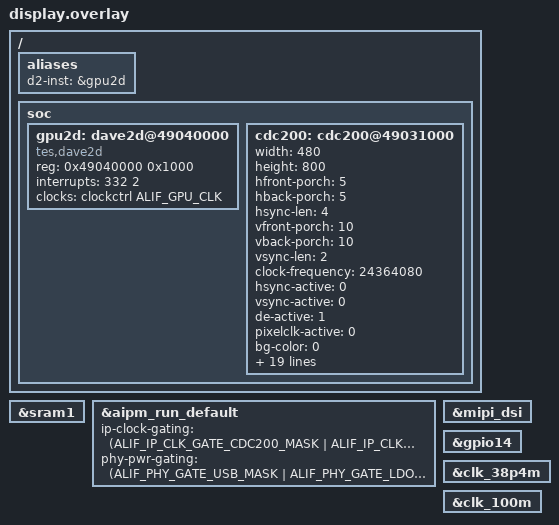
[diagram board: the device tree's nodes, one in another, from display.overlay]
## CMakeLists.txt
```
# Copyright (c) 2026 Alif Semiconductor
# SPDX-License-Identifier: Apache-2.0

cmake_minimum_required(VERSION 3.20.0)
find_package(Zephyr REQUIRED HINTS $ENV{ZEPHYR_BASE})
project(usb_host_uvc)

target_sources(app PRIVATE src/main.c)
target_sources_ifdef(CONFIG_DISPLAY app PRIVATE src/display.c)

# Place USB host DMA buffers in SRAM0
zephyr_linker_sources(DATA_SECTIONS ${CMAKE_CURRENT_SOURCE_DIR}/uhc_dma.ld)
```

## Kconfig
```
# Copyright (c) 2026 Alif Semiconductor
# SPDX-License-Identifier: Apache-2.0

mainmenu "USB Host UVC Capture Sample"

config SAMPLE_UVC_FORMAT_INDEX
	int "Format to stream (bFormatIndex)"
	range 0 255
	default 0
	help
	  bFormatIndex of the video format to request from the device. 0
	  selects the first format the device lists or, with the display, any
	  format the display can show.

config SAMPLE_UVC_FRAME_INDEX
	int "Frame size to stream (bFrameIndex)"
	range 0 255
	default 0
	help
	  bFrameIndex of the frame size to request within the selected format.
	  0 selects the format's default frame (bDefaultFrameIndex) or, with
	  the display, the largest frame the display shows without shrinking
	  it, turned by 90 degrees if need be.

config SAMPLE_UVC_DISPLAY_ROTATE_CCW
	bool "Turn frames counter-clockwise on the display"
	depends on DISPLAY
	help
	  Frames that fill more of the display turned by 90 degrees, such as
	  landscape frames on the DK's portrait panel, are turned clockwise,
	  which puts the top of the picture on the right of the panel. Select
	  this to turn them counter-clockwise instead.

config SAMPLE_UVC_FRAME_BUFFER_SIZE
	int "Frame reassembly buffer size in bytes"
	default 614400
	help
	  Size of the buffer each frame is reassembled into, in SRAM0. The
	  device's dwMaxVideoFrameSize for the negotiated format must fit. The
	  default holds a 640x480 frame at 16 bits per pixel.

config SAMPLE_UVC_TRACE_XFERS
	int "Log the first N transfers"
	range 0 64
	default 0
	help
	  Record the length and first bytes of the first N bulk or isochronous
	  IN transfers after the first stream starts and log them once N have
	  arrived, to debug payload framing. 0 disables the trace.

source "Kconfig.zephyr"
```

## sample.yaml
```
sample:
  name: USB Host UVC Capture
  description: |
    USB host mode sample that enumerates a USB Video Class device streaming
    over a bulk endpoint, negotiates a format with Probe/Commit, reassembles
    frames from the UVC payloads, validates them and logs frame rate and
    throughput. Tested on the E8 DK with an E1C SK running the video_uvc
    sample as the camera. Optionally shows the video on the DK display.
tests:
  sample.drivers.usb.host_uvc:
    extra_args:
      - DTC_OVERLAY_FILE=boards/alif_usb_host.overlay
    integration_platforms:
      - alif_e8_dk/ae822fa0e5597xx0/rtss_hp
    platform_allow:
      - alif_e8_dk/ae822fa0e5597xx0/rtss_hp
      - alif_e8_dk/ae822fa0e5597xx0/rtss_he
      - alif_e7_dk/ae722f80f55d5xx/rtss_hp
      - alif_e7_dk/ae722f80f55d5xx/rtss_he
    tags:
      - usb
      - host
      - video
    harness: keyboard
  sample.drivers.usb.host_uvc.display:
    extra_args:
      - DTC_OVERLAY_FILE=boards/alif_usb_host.overlay
      - EXTRA_DTC_OVERLAY_FILE=display.overlay
      - EXTRA_CONF_FILE=display.conf
    integration_platforms:
      - alif_e8_dk/ae822fa0e5597xx0/rtss_hp
    platform_allow:
      - alif_e8_dk/ae822fa0e5597xx0/rtss_hp
      - alif_e8_dk/ae822fa0e5597xx0/rtss_he
      - alif_e7_dk/ae722f80f55d5xx/rtss_hp
      - alif_e7_dk/ae722f80f55d5xx/rtss_he
    tags:
      - usb
      - host
      - video
      - display
    harness: keyboard
```

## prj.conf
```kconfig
# Copyright (c) 2026 Alif Semiconductor
# SPDX-License-Identifier: Apache-2.0

CONFIG_LOG=y
CONFIG_LOG_DEFAULT_LEVEL=3
CONFIG_LOG_BUFFER_SIZE=16384

CONFIG_USB_HOST_STACK=y
CONFIG_UHC_DWC3=y
CONFIG_UVC_HOST=y

CONFIG_MAIN_STACK_SIZE=4096
CONFIG_SYSTEM_WORKQUEUE_STACK_SIZE=2048
```

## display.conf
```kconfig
# Copyright (c) 2026 Alif Semiconductor
# SPDX-License-Identifier: Apache-2.0

# Show the captured video on the DK display (use with display.overlay)
CONFIG_DISPLAY=y
CONFIG_MIPI_DSI=y
CONFIG_GPIO=y

# Room for a frame as large as the 480x800 panel at 16 bits per pixel
CONFIG_SAMPLE_UVC_FRAME_BUFFER_SIZE=768000

# Turn frames with the D/AVE2D GPU through AIPL, converting YUY2 with
# Helium. Set CONFIG_AIPL=n to draw everything with the CPU.
CONFIG_AIPL=y
CONFIG_DAVE2D=y
CONFIG_AIPL_CUSTOM_VIDEO_ALLOC=n
CONFIG_AIPL_COLOR_CORRECTION=n
CONFIG_AIPL_DEMOSAICING=n
CONFIG_AIPL_CONVERT_YUY2_TO_RGB565=y
```

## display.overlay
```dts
/*
 * Copyright (c) 2026 Alif Semiconductor
 * SPDX-License-Identifier: Apache-2.0
 *
 * Show the captured video on the Ensemble DK display: the MW405 480x800
 * MIPI DSI panel driven by the CDC200 controller, one RGB565 layer. The
 * D/AVE2D GPU turns frames for the portrait panel.
 * Use together with display.conf (see README.rst).
 */

#include <dt-bindings/misc/alif_aipm_common.h>

/ {
	aliases {
		d2-inst = &gpu2d;
	};

	soc {
		gpu2d: dave2d@49040000 {
			compatible = "tes,dave2d";
			reg = <0x49040000 0x1000>;
			interrupts = <332 2>;
			clocks = <&clockctrl ALIF_GPU_CLK>;
		};

		cdc200: cdc200@49031000 {
			width = <480>;
			height = <800>;
			hfront-porch = <5>;
			hback-porch = <5>;
			hsync-len = <4>;
			vfront-porch = <10>;
			vback-porch = <10>;
			vsync-len = <2>;
			clock-frequency = <24364080>;
			hsync-active = <0>;
			vsync-active = <0>;
			de-active = <1>;
			pixelclk-active = <0>;
			bg-color = <0>;
			enable-l1 = <1>;
			pixel-fmt-l1 = "rgb-565";
			def-back-color-l1 = <0>;
			win-x0-l1 = <0>;
			win-y0-l1 = <0>;
			win-x1-l1 = <480>;
			win-y1-l1 = <800>;
			blend-factor1-l1 = <4>;
			blend-factor2-l1 = <5>;
			const-alpha-l1 = <0xff>;
			enable-l2 = <0>;
			pixel-fmt-l2 = "undefined";
			win-x0-l2 = <0>;
			win-y0-l2 = <0>;
			win-x1-l2 = <0>;
			win-y1-l2 = <0>;
			blend-factor1-l2 = <6>;
			blend-factor2-l2 = <7>;
			const-alpha-l2 = <0xff>;
		};
	};
};

/* The D/AVE2D heap and the frame it turns are kept in SRAM1 */
&sram1 {
	status = "okay";
};

/* Keep the USB PHY powered and add the display blocks */
&aipm_run_default {
	ip-clock-gating = <(ALIF_IP_CLK_GATE_CDC200_MASK |
			    ALIF_IP_CLK_GATE_MIPI_DSI_MASK |
			    ALIF_IP_CLK_GATE_GPU_MASK)>;
	phy-pwr-gating = <(ALIF_PHY_GATE_USB_MASK | ALIF_PHY_GATE_LDO_MASK |
			   ALIF_PHY_GATE_MIPI_TX_DPHY_MASK |
			   ALIF_PHY_GATE_MIPI_RX_DPHY_MASK |
			   ALIF_PHY_GATE_MIPI_PLL_DPHY_MASK)>;
};

&mipi_dsi {
	status = "okay";
};

/* Camera/display MIPI switch select on the E4/E6/E8 DK */
&gpio14 {
	status = "okay";
};

&clk_38p4m {
	status = "okay";
};

&clk_100m {
	status = "okay";
};
```

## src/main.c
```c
/*
 * Copyright (c) 2026 Alif Semiconductor
 * SPDX-License-Identifier: Apache-2.0
 *
 * USB Host UVC Capture Sample
 *
 * Brings up the DWC3 controller in host mode and captures video from a USB
 * Video Class (UVC) device that streams over a bulk endpoint, such as an
 * Alif board running the video_uvc sample, or over an isochronous one, such
 * as a webcam:
 *
 *   1. Wait for a device to be connected and enumerate it
 *   2. Parse the configuration descriptor for the VideoStreaming interface,
 *      its formats and frame sizes, and its alternate settings
 *   3. SET_CONFIGURATION and, for bulk, configure the bulk IN endpoint
 *   4. Negotiate a format and frame size with Probe/Commit
 *   5. Isochronous: select the alternate setting that carries the
 *      negotiated payload size and configure its endpoint
 *   6. Keep transfers queued, reassemble frames from the UVC payloads,
 *      validate each frame and log statistics once per second
 *   7. With display.overlay and display.conf, show each valid frame on the
 *      DK display (src/display.c) from a thread of its own
 *
 * Build:
 *   west build -b alif_e8_dk/ae822fa0e5597xx0/rtss_hp \
 *     alif/samples/drivers/usb/usb_host_uvc \
 *     -- -DDTC_OVERLAY_FILE=boards/alif_usb_host.overlay
 */

#include <string.h>

#include <zephyr/kernel.h>
#include <zephyr/device.h>
#include <zephyr/usb/usbh.h>
#include <zephyr/usb/usb_ch9.h>
#include <zephyr/drivers/usb/uhc.h>
#include <zephyr/drivers/usb/uhc_dwc3.h>
#include <zephyr/sys/byteorder.h>

#include "display.h"
#include <zephyr/drivers/usb/uvc_host.h>

#include <zephyr/logging/log.h>
LOG_MODULE_REGISTER(usb_host_uvc, LOG_LEVEL_INF);

#define UHC_NODE DT_NODELABEL(zephyr_uhc0)

#if !DT_NODE_EXISTS(UHC_NODE)
#error "zephyr_uhc0 node not found. Check overlay."
#endif

static const struct device *uhc_dev = DEVICE_DT_GET(UHC_NODE);

USBH_CONTROLLER_DEFINE(sample_uhs_ctx, DEVICE_DT_GET(UHC_NODE));

/* Bulk IN transfers kept in flight, each receiving into its own chunk */
#define NUM_CHUNKS	4
#define CHUNK_SIZE	16384

/*
 * Isochronous IN transfers kept in flight, one per service interval. On
 * High Speed the 32 cover 4 ms. Each buffer holds the most a High-Speed
 * endpoint carries per microframe (3 x 1024 bytes) and is aligned so it
 * never crosses a 64 KiB boundary.
 */
#define NUM_ISO_XFERS	32
#define ISO_BUF_SIZE	4096

/* Wait for a completion before checking that the device is still there */
#define REAP_TIMEOUT_MS	1000

/* A second frame buffer lets the display show one frame while the next is
 * received.
 */
#define NUM_FRAME_BUFS	(IS_ENABLED(CONFIG_DISPLAY) ? 2 : 1)

/*
 * The USB DMA cannot reach TCM, so the chunks live in SRAM0 (placed by
 * uhc_dma.ld). Aligning each chunk to its size keeps it inside one 64 KiB
 * window, as the controller requires. The frame buffer is only written by
 * the CPU but is too large for TCM.
 */
#define SRAM0_SECTION __attribute__((section(".sram0.bss.uhc_dma.uvc")))

static uint8_t chunks[NUM_CHUNKS][CHUNK_SIZE] __aligned(CHUNK_SIZE)
	SRAM0_SECTION;
static uint8_t iso_bufs[NUM_ISO_XFERS][ISO_BUF_SIZE] __aligned(ISO_BUF_SIZE)
	SRAM0_SECTION;
static uint8_t frame_bufs[NUM_FRAME_BUFS][CONFIG_SAMPLE_UVC_FRAME_BUFFER_SIZE]
	__aligned(64) SRAM0_SECTION;
static int frame_buf_idx;

static uint8_t cfg_desc[UHC_DWC3_CTRL_MAX_LEN];
static struct uvc_device uvc;
static struct uvc_stream stream;

/* What the negotiated format lets us check about each frame */
static struct {
	bool mjpeg;
	size_t expected_size;	/* Uncompressed frames: exact size, else 0 */
} check;

static struct {
	uint32_t frames;
	uint32_t bad_frames;
	uint64_t bytes;
	uint32_t timeouts;
	uint32_t lost;		/* Isochronous transfers that lost their data */
	/* Totals across the window, logged once per second */
	uint32_t win_frames;
	uint64_t win_bytes;
	uint32_t win_start;
} stats;

#if CONFIG_SAMPLE_UVC_TRACE_XFERS > 0
static struct {
	uint16_t len;
	uint8_t head[4];
} trace[CONFIG_SAMPLE_UVC_TRACE_XFERS];
static int trace_count;

/* Record a transfer; log them all once the trace is full */
static void trace_xfer(const uint8_t *buf, size_t len, size_t xfer_len)
{
	uint32_t offset = 0;

	if (trace_count >= ARRAY_SIZE(trace)) {
		return;
	}

	trace[trace_count].len = len;
	memcpy(trace[trace_count].head, buf, MIN(len, 4));
	if (++trace_count < ARRAY_SIZE(trace)) {
		return;
	}

	/* Offset is counted from the end of the last short transfer */
	for (int i = 0; i < trace_count; i++) {
		const uint8_t *h = trace[i].head;

		LOG_INF("xfer %3d: off %6u len %5u%s %02x %02x %02x %02x", i,
			offset, trace[i].len,
			trace[i].len < xfer_len ? " short" : "      ",
			h[0], h[1], h[2], h[3]);
		offset = (trace[i].len < xfer_len) ? 0 : offset + trace[i].len;
	}
}
#else
static inline void trace_xfer(const uint8_t *buf, size_t len, size_t xfer_len)
{
}
#endif

static bool port_connected(void)
{
	volatile uint32_t *portsc =
		(volatile uint32_t *)(DT_REG_ADDR(UHC_NODE) + 0x420);

	return (*portsc & BIT(0)) != 0;
}

static int usb_host_event_cb(const struct device *dev,
			     const struct uhc_event *const event)
{
	switch (event->type) {
	case UHC_EVT_DEV_CONNECTED_FS:
		LOG_INF(">>> USB device connected (Full Speed)");
		break;
	case UHC_EVT_DEV_CONNECTED_HS:
		LOG_INF(">>> USB device connected (High Speed)");
		break;
	case UHC_EVT_DEV_REMOVED:
		LOG_INF(">>> USB device disconnected");
		break;
	default:
		break;
	}

	return 0;
}

#if defined(CONFIG_DISPLAY)
/*
 * Frames are drawn by a thread of their own, so that the stream keeps being
 * received meanwhile: an isochronous device does not wait for the host. A
 * frame that completes while the previous one is still being drawn is not
 * shown.
 */
static K_SEM_DEFINE(display_sem, 0, 1);
static atomic_t display_busy;
static const uint8_t *display_buf;
static size_t display_len;

static void display_thread(void *p1, void *p2, void *p3)
{
	ARG_UNUSED(p1);
	ARG_UNUSED(p2);
	ARG_UNUSED(p3);

	while (true) {
		k_sem_take(&display_sem, K_FOREVER);
		uvc_display_frame(display_buf, display_len);
		atomic_clear(&display_busy);
	}
}

K_THREAD_DEFINE(display_tid, 2048, display_thread, NULL, NULL, NULL,
		K_PRIO_PREEMPT(5), 0, 0);

static void show_frame(const uint8_t *frame, size_t len)
{
	if (!atomic_cas(&display_busy, 0, 1)) {
		return;
	}

	display_buf = frame;
	display_len = len;

	/* Receive the next frames into the other buffer meanwhile */
	frame_buf_idx = (frame_buf_idx + 1) % NUM_FRAME_BUFS;
	uvc_stream_set_buffer(&stream, frame_bufs[frame_buf_idx],
			      sizeof(frame_bufs[0]));

	k_sem_give(&display_sem);
}

/* Let the frame being drawn finish before the display format changes */
static void display_wait_idle(void)
{
	while (atomic_get(&display_busy)) {
		k_sleep(K_MSEC(1));
	}
}
#else
static void show_frame(const uint8_t *frame, size_t len)
{
}

static void display_wait_idle(void)
{
}
#endif

/* JPEG: SOI first; EOI last, allowing for a few bytes of zero padding */
static bool jpeg_ok(const uint8_t *frame, size_t len)
{
	size_t end = len;

	if (len < 4 || frame[0] != 0xFF || frame[1] != 0xD8) {
		return false;
	}

	while (end > 2 && len - end < 16 && frame[end - 1] == 0x00) {
		end--;
	}

	return frame[end - 2] == 0xFF && frame[end - 1] == 0xD9;
}

static void frame_done(const uint8_t *frame, size_t len, bool err)
{
	bool bad = err;

	if (!bad && check.mjpeg) {
		bad = !jpeg_ok(frame, len);
	} else if (!bad && check.expected_size != 0) {
		bad = (len != check.expected_size);
	}

	if (stats.frames == 0) {
		LOG_INF("First frame: %zu bytes%s, starts %02x %02x %02x %02x",
			len, bad ? " (bad)" : "", len > 0 ? frame[0] : 0,
			len > 1 ? frame[1] : 0, len > 2 ? frame[2] : 0,
			len > 3 ? frame[3] : 0);
	}

	if (bad && stats.bad_frames < 10) {
		LOG_WRN("Bad frame #%u: %zu bytes (expected %zu)%s", stats.frames,
			len, check.expected_size,
			err ? " (error flagged in stream)" : "");
	}

	if (!bad) {
		show_frame(frame, len);
	}

	stats.frames++;
	stats.bad_frames += bad ? 1 : 0;
	stats.bytes += len;
	stats.win_frames++;
	stats.win_bytes += len;
}

static void log_stats(void)
{
	uint32_t now = k_uptime_get_32();
	uint32_t ms = now - stats.win_start;

	if (ms < 1000) {
		return;
	}

	uint32_t fps_x10 = stats.win_frames * 10000U / ms;
	uint32_t kbps = (uint32_t)(stats.win_bytes / ms); /* bytes/ms = KB/s */

	LOG_INF("%u.%u fps, %u KB/s, avg %u B/frame | frames %u bad %u "
		"| hdr err %u, stream err %u, overflow %u, timeouts %u, lost %u",
		fps_x10 / 10, fps_x10 % 10, kbps,
		stats.win_frames ? (uint32_t)(stats.win_bytes / stats.win_frames) : 0,
		stats.frames, stats.bad_frames, stream.bad_headers,
		stream.err_payloads, stream.overflows, stats.timeouts,
		stats.lost);

	stats.win_frames = 0;
	stats.win_bytes = 0;
	stats.win_start = now;
}

static void list_formats(void)
{
	char name[5];

	LOG_INF("UVC %x.%02x, VideoStreaming interface %u, %s EP 0x%02x mps %u",
		uvc.bcd_uvc >> 8, uvc.bcd_uvc & 0xFF, uvc.vs_iface,
		uvc.ep_type == USB_EP_TYPE_BULK ? "bulk" : "isochronous",
		uvc.ep, uvc.ep_mps);

	for (int i = 0; i < uvc.num_alts; i++) {
		LOG_INF("  Alt %u: %u bytes per interval, bInterval %u",
			uvc.alts[i].alt, uvc_alt_payload(&uvc.alts[i]),
			uvc.alts[i].interval);
	}

	for (int i = 0; i < uvc.num_formats; i++) {
		const struct uvc_format *fmt = &uvc.formats[i];

		LOG_INF("  Format %u: %s%s", fmt->index,
			uvc_format_name(fmt, name),
			fmt->bpp ? "" : " (compressed)");

		for (int j = 0; j < uvc.num_frames; j++) {
			const struct uvc_frame *frm = &uvc.frames[j];

			if (frm->format_index != fmt->index) {
				continue;
			}
			LOG_INF("    Frame %u: %ux%u, default %u.%u fps",
				frm->index, frm->width, frm->height,
				frm->default_interval ?
					10000000U / frm->default_interval : 0,
				frm->default_interval ?
					(100000000U / frm->default_interval) % 10 : 0);
		}
	}
}

/*
 * The largest frame the display shows without shrinking it, of the format
 * selected in Kconfig or, with 0, of any format the display can show.
 */
static const struct uvc_frame *select_display_frame(
	const struct uvc_format **fmt_out)
{
	const struct uvc_frame *best = NULL;
	uint32_t best_area = 0;

	for (int i = 0; i < uvc.num_frames; i++) {
		const struct uvc_frame *frm = &uvc.frames[i];
		const struct uvc_format *fmt =
			uvc_find_format(&uvc, frm->format_index);
		uint32_t area = (uint32_t)frm->width * frm->height;

		if (fmt == NULL ||
		    (CONFIG_SAMPLE_UVC_FORMAT_INDEX != 0 &&
		     fmt->index != CONFIG_SAMPLE_UVC_FORMAT_INDEX) ||
		    !uvc_display_fits(fmt, frm->width, frm->height) ||
		    area * fmt->bpp / 8 > CONFIG_SAMPLE_UVC_FRAME_BUFFER_SIZE ||
		    area <= best_area) {
			continue;
		}

		best = frm;
		best_area = area;
		*fmt_out = fmt;
	}

	return best;
}

/*
 * Pick the format and frame selected in Kconfig (0 = default). With the
 * display and no frame selected, the frame that fills the display best.
 */
static const struct uvc_frame *select_frame(const struct uvc_format **fmt_out)
{
	const struct uvc_format *fmt;
	const struct uvc_frame *frame;
	uint8_t frame_index;

	if (CONFIG_SAMPLE_UVC_FRAME_INDEX == 0) {
		frame = select_display_frame(fmt_out);
		if (frame != NULL) {
			LOG_INF("Format %u frame %u fills the display best",
				frame->format_index, frame->index);
			return frame;
		}
	}

	if (CONFIG_SAMPLE_UVC_FORMAT_INDEX == 0) {
		fmt = &uvc.formats[0];
	} else {
		fmt = uvc_find_format(&uvc, CONFIG_SAMPLE_UVC_FORMAT_INDEX);
	}

	if (fmt == NULL) {
		LOG_ERR("Format %u not found", CONFIG_SAMPLE_UVC_FORMAT_INDEX);
		return NULL;
	}

	frame_index = CONFIG_SAMPLE_UVC_FRAME_INDEX ?
		      CONFIG_SAMPLE_UVC_FRAME_INDEX : fmt->default_frame;

	*fmt_out = fmt;

	return uvc_find_frame(&uvc, fmt->index, frame_index);
}

static int read_config_descriptor(size_t *len)
{
	uint8_t hdr[9];
	uint16_t total;
	int ret;

	ret = uhc_dwc3_control_transfer(uhc_dev, 0x80, USB_SREQ_GET_DESCRIPTOR,
					USB_DESC_CONFIGURATION << 8, 0,
					sizeof(hdr), hdr);
	if (ret < (int)sizeof(hdr)) {
		return ret < 0 ? ret : -EIO;
	}

	total = sys_get_le16(&hdr[2]);
	if (total > sizeof(cfg_desc)) {
		LOG_WRN("Config descriptor is %u bytes, reading the first %zu",
			total, sizeof(cfg_desc));
		total = sizeof(cfg_desc);
	}

	ret = uhc_dwc3_control_transfer(uhc_dev, 0x80, USB_SREQ_GET_DESCRIPTOR,
					USB_DESC_CONFIGURATION << 8, 0,
					total, cfg_desc);
	if (ret < 0) {
		return ret;
	}

	*len = ret;

	return 0;
}

/*
 * Size of each bulk IN transfer: whole packets, at most one chunk. A payload
 * that fills dwMaxPayloadTransferSize ends without a short packet, so the
 * transfers must then split it exactly, or one would run on into the header
 * of the next payload.
 */
static size_t xfer_size(uint32_t max_payload)
{
	size_t step = ROUND_UP(uvc.ep_mps, UHC_DWC3_BUF_ALIGN);
	size_t len = MIN(CHUNK_SIZE, ROUND_UP(max_payload, step));

	if (max_payload % uvc.ep_mps == 0) {
		while (len > step && max_payload % len != 0) {
			len -= step;
		}
	}

	return len;
}

/*
 * Select the isochronous alternate setting that carries the negotiated
 * payloads, configure its endpoint and select it, which starts the stream.
 * Returns the transfer size.
 */
static int start_isoch(uint32_t max_payload)
{
	const struct uvc_alt *alt = uvc_select_alt(&uvc, max_payload);
	uint32_t len;
	int ret;

	if (alt == NULL) {
		LOG_ERR("No alternate setting carries %u byte payloads",
			max_payload);
		return -ENOTSUP;
	}

	len = uvc_alt_payload(alt);
	LOG_INF("Alternate setting %u: %u bytes per interval, bInterval %u",
		alt->alt, len, alt->interval);

	if (len > ISO_BUF_SIZE) {
		return -ENOTSUP;
	}

	ret = uhc_dwc3_configure_isoch_in(uhc_dev, uvc.ep, alt->mps,
					  alt->interval);
	if (ret) {
		LOG_ERR("Configuring EP 0x%02x failed: %d", uvc.ep, ret);
		return ret;
	}

	ret = uhc_dwc3_control_transfer(uhc_dev, 0x01, USB_SREQ_SET_INTERFACE,
					alt->alt, uvc.vs_iface, 0, NULL);
	if (ret < 0) {
		LOG_ERR("SET_INTERFACE %u alt %u failed: %d", uvc.vs_iface,
			alt->alt, ret);
		return ret;
	}

	return len;
}

/* Enumerate the device and get it streaming; returns the transfer size */
static int setup_stream(void)
{
	const struct uvc_format *fmt;
	const struct uvc_frame *frame;
	struct usb_device_descriptor desc;
	struct uvc_probe probe;
	uint32_t max_payload;
	uint32_t max_frame;
	size_t cfg_len;
	char name[5];
	int xfer_len;
	int ret;

	ret = uhc_dwc3_enumerate_device(uhc_dev, &desc);
	if (ret) {
		LOG_ERR("Enumeration failed: %d", ret);
		return ret;
	}

	LOG_INF("Device: VID=0x%04x PID=0x%04x",
		sys_le16_to_cpu(desc.idVendor), sys_le16_to_cpu(desc.idProduct));

	ret = read_config_descriptor(&cfg_len);
	if (ret) {
		LOG_ERR("Reading the config descriptor failed: %d", ret);
		return ret;
	}

	ret = uvc_parse_config(cfg_desc, cfg_len, &uvc);
	if (ret == -ENODEV) {
		LOG_ERR("Not a USB Video Class device");
		return ret;
	} else if (ret) {
		LOG_ERR("No usable VideoStreaming interface found");
		return ret;
	}

	list_formats();

	if (uvc.ep_type != USB_EP_TYPE_BULK && uvc.ep_type != USB_EP_TYPE_ISO) {
		LOG_ERR("Streaming endpoint type %u is not supported",
			uvc.ep_type);
		return -ENOTSUP;
	}

	frame = select_frame(&fmt);
	if (frame == NULL) {
		LOG_ERR("Frame %u not found", CONFIG_SAMPLE_UVC_FRAME_INDEX);
		return -EINVAL;
	}

	ret = uhc_dwc3_control_transfer(uhc_dev, 0x00,
					USB_SREQ_SET_CONFIGURATION,
					uvc.cfg_val, 0, 0, NULL);
	if (ret < 0) {
		LOG_ERR("SET_CONFIGURATION failed: %d", ret);
		return ret;
	}

	if (uvc.ep_type == USB_EP_TYPE_BULK) {
		ret = uhc_dwc3_configure_bulk_in(uhc_dev, uvc.ep, uvc.ep_mps);
		if (ret) {
			LOG_ERR("Configuring EP 0x%02x failed: %d", uvc.ep,
				ret);
			return ret;
		}
	}

	ret = uvc_negotiate(uhc_dev, &uvc, frame, &probe);
	if (ret) {
		return ret;
	}

	/* Go with the format and frame the device settled on */
	if (probe.bFormatIndex != fmt->index ||
	    probe.bFrameIndex != frame->index) {
		fmt = uvc_find_format(&uvc, probe.bFormatIndex);
		frame = uvc_find_frame(&uvc, probe.bFormatIndex,
				       probe.bFrameIndex);
		if (fmt == NULL || frame == NULL) {
			LOG_ERR("Device committed an unknown format/frame");
			return -EINVAL;
		}
	}

	max_payload = sys_le32_to_cpu(probe.dwMaxPayloadTransferSize);
	max_frame = sys_le32_to_cpu(probe.dwMaxVideoFrameSize);

	LOG_INF("Streaming format %u (%s) frame %u: %ux%u, interval %u00 ns",
		fmt->index, uvc_format_name(fmt, name), frame->index,
		frame->width, frame->height,
		sys_le32_to_cpu(probe.dwFrameInterval));
	LOG_INF("  dwMaxVideoFrameSize %u, dwMaxPayloadTransferSize %u",
		max_frame, max_payload);

	if (max_payload == 0) {
		LOG_ERR("Device reported a zero payload size");
		return -EINVAL;
	}

	if (max_frame > sizeof(frame_bufs[0])) {
		LOG_ERR("Frames of up to %u bytes do not fit the %zu byte "
			"buffer, raise CONFIG_SAMPLE_UVC_FRAME_BUFFER_SIZE",
			max_frame, sizeof(frame_bufs[0]));
		return -ENOMEM;
	}

	check.mjpeg = (fmt->subtype == UVC_VS_FORMAT_MJPEG);
	check.expected_size = (fmt->subtype == UVC_VS_FORMAT_UNCOMPRESSED) ?
		(size_t)frame->width * frame->height * fmt->bpp / 8 : 0;

	display_wait_idle();
	uvc_display_set_format(fmt, frame->width, frame->height);

	uvc_stream_init(&stream, max_payload, frame_bufs[frame_buf_idx],
			sizeof(frame_bufs[0]), frame_done);
	memset(&stats, 0, sizeof(stats));
	stats.win_start = k_uptime_get_32();

	if (uvc.ep_type == USB_EP_TYPE_ISO) {
		xfer_len = start_isoch(max_payload);
	} else {
		xfer_len = xfer_size(max_payload);
	}

	return xfer_len;
}

/* Receive until the device goes away or the stream fails */
static void run_isoch(size_t xfer_len)
{
	uint8_t *buf;
	int ret;

	for (int i = 0; i < NUM_ISO_XFERS; i++) {
		ret = uhc_dwc3_isoch_in_submit(uhc_dev, iso_bufs[i], xfer_len);
		if (ret) {
			LOG_ERR("Submitting transfer %d failed: %d", i, ret);
			return;
		}
	}

	while (true) {
		ret = uhc_dwc3_isoch_in_reap(uhc_dev, &buf, REAP_TIMEOUT_MS);
		if (ret == -EAGAIN) {
			/* A streaming isochronous endpoint completes a
			 * transfer every interval, also with no data.
			 */
			stats.timeouts++;
			if (!port_connected()) {
				LOG_INF("Device disconnected");
			} else {
				LOG_ERR("Isochronous stream stopped");
			}
			return;
		}

		if (ret == -ENODATA || ret == -EIO) {
			stats.lost++;
			uvc_stream_lost(&stream);
		} else if (ret >= 0) {
			trace_xfer(buf, ret, xfer_len);
			uvc_stream_feed(&stream, buf, ret, true);
		} else {
			LOG_ERR("Isochronous IN failed: %d", ret);
			return;
		}

		ret = uhc_dwc3_isoch_in_submit(uhc_dev, buf, xfer_len);
		if (ret) {
			LOG_ERR("Resubmitting transfer failed: %d", ret);
			return;
		}

		log_stats();
	}
}

static void run_bulk(size_t xfer_len)
{
	uint8_t *buf;
	int ret;

	for (int i = 0; i < NUM_CHUNKS; i++) {
		ret = uhc_dwc3_bulk_in_submit(uhc_dev, chunks[i], xfer_len);
		if (ret) {
			LOG_ERR("Submitting transfer %d failed: %d", i, ret);
			return;
		}
	}

	while (true) {
		ret = uhc_dwc3_bulk_in_reap(uhc_dev, &buf, REAP_TIMEOUT_MS);
		if (ret == -EAGAIN) {
			stats.timeouts++;
			if (!port_connected()) {
				LOG_INF("Device disconnected");
				return;
			}
			LOG_WRN("No video data for %u ms", REAP_TIMEOUT_MS);
			continue;
		} else if (ret < 0) {
			LOG_ERR("Bulk IN failed: %d", ret);
			return;
		}

		trace_xfer(buf, ret, xfer_len);
		uvc_stream_feed(&stream, buf, ret, (size_t)ret < xfer_len);

		ret = uhc_dwc3_bulk_in_submit(uhc_dev, buf, xfer_len);
		if (ret) {
			LOG_ERR("Resubmitting transfer failed: %d", ret);
			return;
		}

		log_stats();
	}
}

int main(void)
{
	int ret;

	LOG_INF("USB Host UVC Capture Sample");
	LOG_INF("===========================");

	if (!device_is_ready(uhc_dev)) {
		LOG_ERR("USB host controller device not ready");
		return -ENODEV;
	}

	ret = uhc_init(uhc_dev, usb_host_event_cb, &sample_uhs_ctx);
	if (ret) {
		LOG_ERR("Failed to initialize UHC: %d", ret);
		return ret;
	}

	ret = uhc_enable(uhc_dev);
	if (ret) {
		LOG_ERR("Failed to enable UHC: %d", ret);
		return ret;
	}

	/* Without a working display the sample still captures and checks */
	if (uvc_display_init() != 0) {
		LOG_WRN("Continuing without the display");
	}

	LOG_INF("Waiting for a USB video device...");

	while (true) {
		k_sleep(K_SECONDS(1));

		if (!port_connected()) {
			continue;
		}

		LOG_INF("Device detected, enumerating...");
		k_sleep(K_MSEC(500)); /* Let the device settle */

		ret = setup_stream();
		if (ret < 0) {
			LOG_INF("Retrying in 5 seconds...");
			k_sleep(K_SECONDS(5));
			continue;
		}

		/* Returns when the device is unplugged or the stream fails;
		 * a device that is still attached is enumerated again.
		 */
		if (uvc.ep_type == USB_EP_TYPE_ISO) {
			run_isoch(ret);
		} else {
			run_bulk(ret);
		}
		log_stats();
	}

	return 0;
}
```

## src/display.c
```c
/*
 * Copyright (c) 2026 Alif Semiconductor
 * SPDX-License-Identifier: Apache-2.0
 *
 * Shows each captured frame centred on the DK display. The CDC200 layer is
 * RGB565, so RGB565 ("RGBP") frames are copied as they are and YUY2 frames
 * are converted. A frame is turned by 90 degrees when it fills more of the
 * panel that way, e.g. a landscape frame on a portrait panel, and frames
 * larger than the panel are shrunk by an integer factor (nearest neighbour).
 *
 * Drawing a frame takes longer than the panel takes to refresh, so frames
 * are drawn into a framebuffer that is not on screen, which is then put on
 * screen in the vertical blanking (cdc200_swap_fb()). Without that, the
 * panel would show part of the old and part of the new frame.
 *
 * With AIPL (CONFIG_AIPL), turned frames are drawn by the D/AVE2D GPU: YUY2
 * frames are first converted to RGB565 with AIPL's Helium code, as D/AVE2D
 * cannot read YUY2, then D/AVE2D turns the RGB565 frame straight into the
 * framebuffer, in narrow strips. Other frames, and turned ones if the GPU
 * fails, are drawn by the CPU.
 */

#include <string.h>

#include <zephyr/kernel.h>
#include <zephyr/cache.h>
#include <zephyr/device.h>
#include <zephyr/init.h>
#include <zephyr/drivers/display.h>
#include <zephyr/drivers/display/cdc200.h>
#include <zephyr/drivers/gpio.h>
#include <zephyr/drivers/mipi_dsi/dsi_dw.h>
#include <zephyr/linker/section_tags.h>
#include <zephyr/sys/byteorder.h>

#if defined(CONFIG_AIPL)
#include <aipl_cache.h>
#include <aipl_color_conversion.h>
#include <aipl_dave2d.h>
#include <dave_d0lib.h>
#endif

#include "display.h"

#include <zephyr/logging/log.h>
LOG_MODULE_REGISTER(uvc_display, LOG_LEVEL_INF);

#define DISPLAY_NODE	DT_CHOSEN(zephyr_display)
#define DSI_NODE	DT_ALIAS(mipi_dsi)
#define PANEL_NODE	DT_ALIAS(panel)

/* RGB565 framebuffer the size of the panel */
#define FB_SIZE		(DT_PROP(DISPLAY_NODE, width) * \
			 DT_PROP(DISPLAY_NODE, height) * sizeof(uint16_t))

/*
 * Panel rows built at a time when turning a frame. Each panel row is a
 * column of the frame, so building several at once reads the frame a few
 * neighbouring pixels at a time instead of one pixel per frame row.
 */
#define ROTATE_ROWS	16

/* How long a buffer swap may take: the next vertical blanking */
#define SWAP_TIMEOUT	K_MSEC(100)

/* Frames drawn between logs of the time drawing takes */
#define DRAW_LOG_FRAMES	100

static const struct device *const display_dev = DEVICE_DT_GET(DISPLAY_NODE);

static uint16_t panel_w;
static uint16_t panel_h;
static bool ready;

/*
 * The driver's framebuffer and a second one, in SRAM0 like the driver's,
 * which the CDC200 reads. fbs[back] is the one not on screen.
 */
static uint8_t fb1[FB_SIZE] __aligned(64) __alif_sram0_section;
static uint8_t *fbs[2];
static int back;

/* A swap was requested and fbs[back] may still be on screen */
static bool swap_pending;

/* Time the frame being drawn spent in wait_swap() */
static uint32_t frame_wait_cycles;

/* Time spent drawing frames, logged every DRAW_LOG_FRAMES frames */
static struct {
	uint32_t frames;
	uint32_t gpu_frames;
	uint64_t cycles;	/* Whole draw, without the swap */
	uint64_t convert_cycles; /* GPU path: YUY2 -> RGB565 with Helium */
	uint64_t flush_cycles;	/* GPU path: writing the RGB565 frame back */
	uint64_t gpu_cycles;	/* GPU path: D/AVE2D, invalidate overlapped */
	uint64_t swap_cycles;	/* Waiting for the previous buffer swap */
} draw_stats;

/* Where and how the current format is drawn */
static struct {
	bool ok;
	bool yuy2;
	bool rotate;		/* Turned by 90 degrees */
	uint16_t width;		/* Source frame */
	uint16_t height;
	uint16_t step;		/* Shrink factor */
	uint16_t out_w;		/* On the panel */
	uint16_t out_h;
	uint16_t x;
	uint16_t y;
} view;

#if DT_NODE_HAS_PROP(DSI_NODE, cam_disp_mux_gpios)
/*
 * Route the shared MIPI D-PHY lanes to the display (E4/E6/E8 DK) before the
 * panel driver sends its initialisation commands over DSI.
 */
static int select_display_mux(void)
{
	const struct gpio_dt_spec mux =
		GPIO_DT_SPEC_GET(DSI_NODE, cam_disp_mux_gpios);

	if (!gpio_is_ready_dt(&mux)) {
		return -ENODEV;
	}

	return gpio_pin_configure_dt(&mux, GPIO_OUTPUT_ACTIVE);
}

SYS_INIT(select_display_mux, PRE_KERNEL_1, 46);
#endif

/* Pixel (x, y) of the framebuffer not on screen */
static inline uint16_t *back_pixel(uint16_t x, uint16_t y)
{
	return (uint16_t *)fbs[back] + (size_t)y * panel_w + x;
}

/* Put the framebuffer drawn into on screen and draw into the other one */
/*
 * Have the framebuffer drawn into put on screen in the next vertical
 * blanking and draw into the other one, once that has left the screen:
 * see wait_swap().
 */
static void request_swap(void)
{
	struct cdc200_fb_desc fb = {
		.fb_addr = fbs[back],
		.fb_size = FB_SIZE,
	};

	cdc200_swap_fb(display_dev, 0, &fb);
	swap_pending = true;
	back ^= 1;
}

/*
 * Wait until the framebuffer to draw into is no longer on screen. Called
 * just before writing it, so that the next frame can be prepared (e.g. a
 * YUY2 conversion) while the swap is still pending.
 */
static void wait_swap(void)
{
	uint32_t start;

	if (!swap_pending) {
		return;
	}

	start = k_cycle_get_32();
	if (cdc200_wait_vsync(display_dev, SWAP_TIMEOUT) != 0) {
		LOG_WRN("Framebuffer swap timed out");
	}
	swap_pending = false;

	frame_wait_cycles += k_cycle_get_32() - start;
}

static void clear_screen(void)
{
	wait_swap();

	for (int i = 0; i < ARRAY_SIZE(fbs); i++) {
		memset(fbs[i], 0, FB_SIZE);
		sys_cache_data_flush_range(fbs[i], FB_SIZE);
	}
}

static void gpu_init(void);

int uvc_display_init(void)
{
	const struct device *dsi = DEVICE_DT_GET(DSI_NODE);
	struct display_capabilities caps;
	struct cdc200_fb_desc fb;
	int ret;

	if (!device_is_ready(dsi) || !device_is_ready(display_dev)) {
		LOG_ERR("Display not ready");
		return -ENODEV;
	}

	ret = dsi_dw_set_mode(dsi, DSI_DW_VIDEO_MODE);
	if (ret) {
		LOG_ERR("Setting DSI video mode failed: %d", ret);
		return ret;
	}

#if DT_NODE_HAS_STATUS(PANEL_NODE, okay)
	const struct device *panel = DEVICE_DT_GET(PANEL_NODE);

	if (!device_is_ready(panel) || display_blanking_off(panel) != 0) {
		LOG_WRN("Display panel not ready, continuing");
	}
#endif

	cdc200_set_enable(display_dev, true);

	display_get_capabilities(display_dev, &caps);
	cdc200_get_framebuffer(display_dev, 0, &fb);
	if (caps.current_pixel_format != PIXEL_FORMAT_RGB_565 ||
	    fb.fb_size != FB_SIZE) {
		LOG_ERR("Display must be one full-screen RGB565 layer");
		return -ENOTSUP;
	}

	panel_w = caps.x_resolution;
	panel_h = caps.y_resolution;
	fbs[0] = fb.fb_addr;
	fbs[1] = fb1;
	back = 1;
	ready = true;

	clear_screen();
	gpu_init();

	LOG_INF("Display %ux%u ready", panel_w, panel_h);

	return 0;
}

static bool is_yuy2(const struct uvc_format *fmt)
{
	return fmt->subtype == UVC_VS_FORMAT_UNCOMPRESSED &&
	       memcmp(fmt->guid, "YUY2", 4) == 0;
}

static bool can_show(const struct uvc_format *fmt)
{
	return is_yuy2(fmt) ||
	       (fmt->subtype == UVC_VS_FORMAT_UNCOMPRESSED &&
		memcmp(fmt->guid, "RGBP", 4) == 0);
}

bool uvc_display_fits(const struct uvc_format *fmt, uint16_t width,
		      uint16_t height)
{
	if (!ready || !can_show(fmt)) {
		return false;
	}

	return (width <= panel_w && height <= panel_h) ||
	       (height <= panel_w && width <= panel_h);
}

/* Shrink factor that fits a w x h picture on the panel */
static uint16_t fit_step(uint16_t w, uint16_t h)
{
	return MAX(DIV_ROUND_UP(w, panel_w), DIV_ROUND_UP(h, panel_h));
}

bool uvc_display_set_format(const struct uvc_format *fmt, uint16_t width,
			    uint16_t height)
{
	uint16_t step = fit_step(width, height);
	uint16_t rot_step = fit_step(height, width);
	uint32_t area = (uint32_t)(width / step) * (height / step);
	uint32_t rot_area = (uint32_t)(height / rot_step) * (width / rot_step);

	view.ok = false;

	if (!ready) {
		return false;
	}

	if (!can_show(fmt)) {
		LOG_WRN("Format cannot be shown, only RGB565 and YUY2 can");
		clear_screen();
		return false;
	}

	/* Turn the picture if it then fills more of the panel */
	view.rotate = rot_area > area;
	if (view.rotate) {
		step = rot_step;
	}

	view.yuy2 = is_yuy2(fmt);
	view.width = width;
	view.height = height;
	view.step = step;
	view.out_w = (view.rotate ? height : width) / step;
	view.out_h = (view.rotate ? width : height) / step;
	view.x = (panel_w - view.out_w) / 2;
	view.y = (panel_h - view.out_h) / 2;
	view.ok = true;

	/* Drop whatever an earlier stream left around the picture */
	clear_screen();

	LOG_INF("Showing %ux%u as %ux%u at (%u, %u)%s", width, height,
		view.out_w, view.out_h, view.x, view.y,
		!view.rotate ? "" :
		IS_ENABLED(CONFIG_SAMPLE_UVC_DISPLAY_ROTATE_CCW) ?
		", turned counter-clockwise" : ", turned clockwise");

	return true;
}

static uint16_t yuv_to_rgb565(int y, int u, int v)
{
	/* ITU-R BT.601, limited range */
	int c = 298 * (y - 16) + 128;
	int d = u - 128;
	int e = v - 128;
	int r = CLAMP((c + 409 * e) >> 8, 0, 255);
	int g = CLAMP((c - 100 * d - 208 * e) >> 8, 0, 255);
	int b = CLAMP((c + 516 * d) >> 8, 0, 255);

	return ((r & 0xF8) << 8) | ((g & 0xFC) << 3) | (b >> 3);
}

/* Pixel @p col of frame row @p src as RGB565 */
static inline uint16_t src_pixel(const uint8_t *src, uint32_t col)
{
	if (view.yuy2) {
		/* Y0 U Y1 V: each pair of pixels shares U and V */
		const uint8_t *pair = &src[(col & ~1U) * 2];

		return yuv_to_rgb565(src[col * 2], pair[1], pair[3]);
	}

	return sys_get_le16(&src[col * 2]);
}

static void convert_row(const uint8_t *src, uint16_t *dst)
{
	for (uint16_t i = 0; i < view.out_w; i++) {
		dst[i] = src_pixel(src, (uint32_t)i * view.step);
	}
}

/*
 * Draw the frame turned by 90 degrees: each panel row is a frame column.
 * Clockwise, the top of the frame ends up on the right of the panel;
 * counter-clockwise, on the left.
 */
static void draw_rotated(const uint8_t *frame, size_t stride)
{
	const bool ccw = IS_ENABLED(CONFIG_SAMPLE_UVC_DISPLAY_ROTATE_CCW);

	for (uint16_t y0 = 0; y0 < view.out_h; y0 += ROTATE_ROWS) {
		uint16_t rows = MIN(ROTATE_ROWS, view.out_h - y0);
		uint16_t *dst = back_pixel(view.x, view.y + y0);

		for (uint16_t x = 0; x < view.out_w; x++) {
			uint32_t src_row = ccw ? x : (view.out_w - 1 - x);
			const uint8_t *src =
				&frame[src_row * view.step * stride];

			for (uint16_t r = 0; r < rows; r++) {
				uint32_t y = y0 + r;
				uint32_t col = ccw ? (view.out_h - 1 - y) : y;

				dst[r * panel_w + x] =
					src_pixel(src, col * view.step);
			}
		}
	}
}

#if defined(CONFIG_AIPL)
/* Display lists and other memory of the D/AVE2D driver */
#define D0_HEAP_SIZE	(256 * 1024)

/*
 * Width of the strips D/AVE2D draws a turned frame in. In a strip w panel
 * columns wide, each panel row reads one pixel from each of w frame rows,
 * and the next panel row the pixels next to those. Measured on the E8 with
 * 800x448 frames, the texture cache holds about 8 frame rows: up to 8 wide
 * nearly every read hits and the time halves with each doubling of the
 * width, as the panel rows are written in longer pieces (31 ms at 1 wide,
 * 5 ms at 8), while at 16 and 32 every read misses (41 ms).
 */
#define ROTATE_STRIP_WIDTH	8

static uint8_t d0_heap[D0_HEAP_SIZE] __aligned(64) __alif_sram1_section;

/* A YUY2 frame converted to RGB565 for D/AVE2D. Only frames that fit the
 * panel are turned, so a framebuffer's worth is enough.
 */
static uint8_t rgb_frame[FB_SIZE] __aligned(64) __alif_sram1_section;

static bool gpu_ready;


/* Cache maintenance AIPL does around D/AVE2D accesses */
void aipl_cpu_cache_clean(const void *ptr, uint32_t size)
{
	sys_cache_data_flush_range((void *)ptr, size);
}

void aipl_cpu_cache_invalidate(const void *ptr, uint32_t size)
{
	sys_cache_data_invd_range((void *)ptr, size);
}

static void gpu_init(void)
{
#if defined(CONFIG_D1_MALLOC_D0LIB)
	if (!d0_initheapmanager(d0_heap, sizeof(d0_heap), d0_mm_fixed_range,
				NULL, 0, 0, 0, d0_ma_unified)) {
		LOG_ERR("D/AVE2D heap initialisation failed");
		return;
	}
#endif

	if (aipl_dave2d_init() != D2_OK) {
		LOG_ERR("D/AVE2D initialisation failed, drawing with the CPU");
		return;
	}

	gpu_ready = true;
}

/* Keep the first D/AVE2D error of a sequence of calls */
static inline void d2_check(d2_s32 *ret, d2_s32 result)
{
	if (*ret == D2_OK) {
		*ret = result;
	}
}

/*
 * Turn an RGB565 frame into the framebuffer not on screen with D/AVE2D,
 * drawn as textured boxes ROTATE_STRIP_WIDTH panel columns wide.
 */
static d2_s32 gpu_rotate(const void *src)
{
	const bool ccw = IS_ENABLED(CONFIG_SAMPLE_UVC_DISPLAY_ROTATE_CCW);
	d2_device *d2 = aipl_dave2d_handle();
	/* Panel pixel that shows the first frame pixel */
	d2_point x0 = view.x + (ccw ? 0 : view.out_w - 1);
	d2_point y0 = view.y + (ccw ? view.out_h - 1 : 0);
	/* Frame column per panel row down, frame row per panel column across */
	d2_s32 dyu = ccw ? -D2_FIX16(1) : D2_FIX16(1);
	d2_s32 dxv = ccw ? D2_FIX16(1) : -D2_FIX16(1);
	d2_s32 ret = D2_OK;

	d2_check(&ret, d2_startframe(d2));
	d2_check(&ret, d2_framebuffer(d2, fbs[back], panel_w, panel_w,
				      panel_h, d2_mode_rgb565));

	/* Opaque copy of the texture */
	d2_check(&ret, d2_settextureoperation(d2, d2_to_one, d2_to_copy,
					      d2_to_copy, d2_to_copy));
	d2_check(&ret, d2_settexture(d2, (void *)src, view.width, view.width,
				     view.height, d2_mode_rgb565));
	d2_check(&ret, d2_settexturemode(d2, 0));
	d2_check(&ret, d2_setfillmode(d2, d2_fm_texture));
	d2_check(&ret, d2_setblendmode(d2, d2_bm_alpha,
				       d2_bm_one_minus_alpha));
	d2_check(&ret, d2_setalphablendmode(d2, d2_bm_one,
					    d2_bm_one_minus_alpha));

	/*
	 * Clockwise, the frame top is on the right, so each panel column to
	 * the left is the next frame row; counter-clockwise, to the right.
	 */
	d2_check(&ret, d2_settexturemapping(d2, D2_FIX4(x0), D2_FIX4(y0), 0, 0,
					    0, dyu, dxv, 0));

	for (uint16_t x = 0; x < view.out_w; x += ROTATE_STRIP_WIDTH) {
		uint16_t w = MIN(ROTATE_STRIP_WIDTH, view.out_w - x);

		d2_check(&ret, d2_renderbox(d2, D2_FIX4(view.x + x),
					    D2_FIX4(view.y), D2_FIX4(w),
					    D2_FIX4(view.out_h)));
	}

	/* Close the display list and start it */
	d2_check(&ret, d2_endframe(d2));
	d2_check(&ret, d2_startframe(d2));

	/*
	 * Drop cached framebuffer lines while D/AVE2D draws, so that none is
	 * written back over the picture later
	 */
	sys_cache_data_invd_range(back_pixel(0, view.y),
				  (size_t)view.out_h * panel_w *
				  sizeof(uint16_t));

	/* Wait for the drawing to finish */
	d2_check(&ret, d2_endframe(d2));

	return ret;
}

/* Turn the frame into the framebuffer not on screen with D/AVE2D */
static bool draw_rotated_gpu(const uint8_t *frame)
{
	const void *src = frame;
	aipl_error_t err;
	d2_s32 ret;

	uint32_t t0 = k_cycle_get_32();
	uint32_t t1;

	if (!gpu_ready || view.step != 1) {
		return false;
	}

	if (view.yuy2) {
		err = aipl_color_convert_yuy2_to_rgb565(frame, rgb_frame,
							view.width, view.width,
							view.height);
		if (err != AIPL_ERR_OK) {
			LOG_ERR("YUY2 conversion failed: %d", err);
			gpu_ready = false;
			return false;
		}
		src = rgb_frame;
	}

	t1 = k_cycle_get_32();
	draw_stats.convert_cycles += t1 - t0;

	/* D/AVE2D reads the frame from memory */
	sys_cache_data_flush_range((void *)src,
				   (size_t)view.width * view.height *
				   sizeof(uint16_t));

	draw_stats.flush_cycles += k_cycle_get_32() - t1;

	wait_swap();

	t0 = k_cycle_get_32();
	ret = gpu_rotate(src);
	if (ret != D2_OK) {
		LOG_ERR("D/AVE2D rotation failed: %d, drawing with the CPU",
			(int)ret);
		gpu_ready = false;
		return false;
	}

	draw_stats.gpu_cycles += k_cycle_get_32() - t0;

	return true;
}
#else
static void gpu_init(void)
{
}

static bool draw_rotated_gpu(const uint8_t *frame)
{
	return false;
}
#endif

/* Average of a cycle total over the frames counted, in us */
static uint32_t avg_us(uint64_t cycles, uint32_t frames)
{
	return frames ? k_cyc_to_us_floor32(cycles / frames) : 0;
}

static void log_draw_time(bool gpu, uint32_t start)
{
	static uint32_t last_log_ms;
	uint32_t now = k_uptime_get_32();
	uint32_t fps_x10;

	draw_stats.cycles += k_cycle_get_32() - start - frame_wait_cycles;
	draw_stats.swap_cycles += frame_wait_cycles;
	draw_stats.gpu_frames += gpu;

	if (++draw_stats.frames < DRAW_LOG_FRAMES) {
		return;
	}

	/* Frames shown per second since the last log; the first is rough */
	fps_x10 = (now > last_log_ms) ?
		  draw_stats.frames * 10000U / (now - last_log_ms) : 0;
	last_log_ms = now;

	LOG_INF("%u.%u fps on screen; drawing a frame takes %u us on average, "
		"plus %u us waiting for the previous swap (%u of %u by the GPU)",
		fps_x10 / 10, fps_x10 % 10,
		avg_us(draw_stats.cycles, draw_stats.frames),
		avg_us(draw_stats.swap_cycles, draw_stats.frames),
		draw_stats.gpu_frames, draw_stats.frames);

	if (draw_stats.gpu_frames > 0) {
		LOG_INF("  GPU frames: YUY2 conversion %u us, cache flush %u us, "
			"D/AVE2D rotation %u us",
			avg_us(draw_stats.convert_cycles, draw_stats.gpu_frames),
			avg_us(draw_stats.flush_cycles, draw_stats.gpu_frames),
			avg_us(draw_stats.gpu_cycles, draw_stats.gpu_frames));
	}

	memset(&draw_stats, 0, sizeof(draw_stats));
}

/* Draw the frame into the framebuffer not on screen with the CPU */
static void draw_cpu(const uint8_t *frame, size_t stride)
{
	if (view.rotate) {
		draw_rotated(frame, stride);
	} else if (!view.yuy2 && view.step == 1) {
		for (uint16_t row = 0; row < view.out_h; row++) {
			memcpy(back_pixel(view.x, view.y + row),
			       &frame[row * stride], stride);
		}
	} else {
		for (uint16_t row = 0; row < view.out_h; row++) {
			convert_row(&frame[(size_t)row * view.step * stride],
				    back_pixel(view.x, view.y + row));
		}
	}

	/* The CDC200 reads the framebuffer from memory */
	sys_cache_data_flush_range(back_pixel(0, view.y),
				   (size_t)view.out_h * panel_w *
				   sizeof(uint16_t));
}

void uvc_display_frame(const uint8_t *frame, size_t len)
{
	size_t stride = (size_t)view.width * 2;
	uint32_t start = k_cycle_get_32();
	bool gpu = false;

	if (!view.ok || len < stride * view.height) {
		return;
	}

	frame_wait_cycles = 0;

	/* The GPU path waits for the swap itself, after the conversion */
	if (view.rotate) {
		gpu = draw_rotated_gpu(frame);
	}

	if (!gpu) {
		wait_swap();
		draw_cpu(frame, stride);
	}

	request_swap();

	log_draw_time(gpu, start);
}
```

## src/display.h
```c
/*
 * Copyright (c) 2026 Alif Semiconductor
 * SPDX-License-Identifier: Apache-2.0
 *
 * Rendering of captured frames on the DK display (CDC200 + MIPI DSI panel).
 */

#ifndef USB_HOST_UVC_DISPLAY_H_
#define USB_HOST_UVC_DISPLAY_H_

#include <stddef.h>
#include <stdint.h>

#include <zephyr/drivers/usb/uvc_host.h>

#if defined(CONFIG_DISPLAY)

/* Bring up the DSI link, panel and display controller; clear the screen */
int uvc_display_init(void);

/*
 * Whether frames of this format and size can be shown without shrinking
 * them, turned by 90 degrees if need be.
 */
bool uvc_display_fits(const struct uvc_format *fmt, uint16_t width,
		      uint16_t height);

/*
 * Select the format and size of the frames to show next. Returns false if
 * the format cannot be shown, in which case frames are ignored.
 */
bool uvc_display_set_format(const struct uvc_format *fmt, uint16_t width,
			    uint16_t height);

/* Show one complete frame of the format set with uvc_display_set_format() */
void uvc_display_frame(const uint8_t *frame, size_t len);

#else

static inline int uvc_display_init(void)
{
	return 0;
}

static inline bool uvc_display_fits(const struct uvc_format *fmt,
				    uint16_t width, uint16_t height)
{
	return false;
}

static inline bool uvc_display_set_format(const struct uvc_format *fmt,
					  uint16_t width, uint16_t height)
{
	return false;
}

static inline void uvc_display_frame(const uint8_t *frame, size_t len)
{
}

#endif /* CONFIG_DISPLAY */

#endif /* USB_HOST_UVC_DISPLAY_H_ */
```
